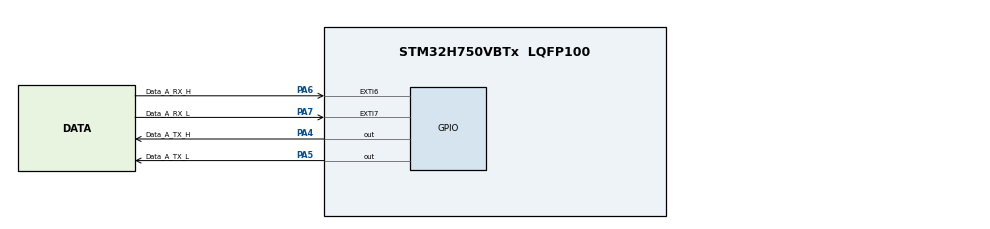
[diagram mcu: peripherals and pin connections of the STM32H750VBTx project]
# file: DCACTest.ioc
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CORTEX_M7.CPU_DCache=Enabled
CORTEX_M7.CPU_ICache=Enabled
FREERTOS.Tasks01=defaultTask,24,128,StartDefaultTask,Default,NULL,Dynamic,NULL,NULL
FREERTOS.configENABLE_FPU=0
Mcu.Family=STM32H7
Mcu.Name=STM32H750VBTx
Mcu.Package=LQFP100
NVIC.EXTI9_5_IRQn=true\:5\:0\:false\:false\:true\:true\:true\:true\:true
NVIC.PriorityGroup=NVIC_PRIORITYGROUP_4
NVIC.TIM5_IRQn=true\:15\:0\:false\:false\:true\:false\:false\:true\:true
NVIC.TimeBase=TIM5_IRQn
NVIC.TimeBaseIP=TIM5
PA13\ (JTMS/SWDIO).Mode=Serial_Wire
PA13\ (JTMS/SWDIO).Signal=DEBUG_JTMS-SWDIO
PA14\ (JTCK/SWCLK).Mode=Serial_Wire
PA14\ (JTCK/SWCLK).Signal=DEBUG_JTCK-SWCLK
PA4.GPIO_Label=Data_A_TX_H
PA4.GPIO_Speed=GPIO_SPEED_FREQ_VERY_HIGH
PA4.PinState=GPIO_PIN_SET
PA4.Signal=GPIO_Output
PA5.GPIO_Label=Data_A_TX_L
PA5.GPIO_Speed=GPIO_SPEED_FREQ_VERY_HIGH
PA5.PinState=GPIO_PIN_SET
PA5.Signal=GPIO_Output
PA6.GPIO_Label=Data_A_RX_H
PA6.GPIO_ModeDefaultEXTI=GPIO_MODE_IT_FALLING
PA6.GPIO_PuPd=GPIO_PULLUP
PA6.Signal=GPXTI6
PA7.GPIO_Label=Data_A_RX_L
PA7.GPIO_ModeDefaultEXTI=GPIO_MODE_IT_FALLING
PA7.GPIO_PuPd=GPIO_PULLUP
PA7.Signal=GPXTI7
PH0-OSC_IN\ (PH0).Mode=HSE-External-Oscillator
PH0-OSC_IN\ (PH0).Signal=RCC_OSC_IN
PH1-OSC_OUT\ (PH1).Mode=HSE-External-Oscillator
PH1-OSC_OUT\ (PH1).Signal=RCC_OSC_OUT
ProjectManager.HeapSize=0x200
ProjectManager.StackSize=0x400
ProjectManager.TargetToolchain=MDK-ARM V5.32
RCC.ADCFreq_Value=50390625
RCC.APB1Freq_Value=120000000
RCC.APB2Freq_Value=120000000
RCC.APB3Freq_Value=120000000
RCC.APB4Freq_Value=120000000
RCC.CortexFreq_Value=480000000
RCC.D1PPRE=RCC_APB3_DIV2
RCC.D2PPRE1=RCC_APB1_DIV2
RCC.D2PPRE2=RCC_APB2_DIV2
RCC.D3PPRE=RCC_APB4_DIV2
RCC.DIVM1=5
RCC.DIVN1=192
RCC.HCLKFreq_Value=240000000
RCC.HPRE=RCC_HCLK_DIV2
RCC.PLLSourceVirtual=RCC_PLLSOURCE_HSE
RCC.SYSCLKFreq_VALUE=480000000
RCC.SYSCLKSource=RCC_SYSCLKSOURCE_PLLCLK
RCC.USBFreq_Value=480000000
TIM6.Prescaler=240-1
VP_FREERTOS_VS_CMSIS_V2.Mode=CMSIS_V2
VP_SYS_VS_tim5.Mode=TIM5
VP_TIM6_VS_ClockSourceINT.Mode=Enable_Timer
board=custom

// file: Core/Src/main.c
/* USER CODE BEGIN Header */
/**
  ******************************************************************************
  * @file           : main.c
  * @brief          : Main program body
  ******************************************************************************
  * @attention
  *
  * Copyright (c) 2023 STMicroelectronics.
  * All rights reserved.
  *
  * This software is licensed under terms that can be found in the LICENSE file
  * in the root directory of this software component.
  * If no LICENSE file comes with this software, it is provided AS-IS.
  *
  ******************************************************************************
  */
/* USER CODE END Header */
#include "main.h"
#include "cmsis_os.h"
#include "tim.h"
#include "gpio.h"

/* USER CODE BEGIN Includes */
#include "usDelay.h"
/* USER CODE END Includes */

/* USER CODE BEGIN PTD */
uint32_t timer = 0;
/* USER CODE END PTD */

void SystemClock_Config(void);
void MX_FREERTOS_Init(void);

int main(void)
{

  /* Enable I-Cache---------------------------------------------------------*/
  SCB_EnableICache();

  /* Enable D-Cache---------------------------------------------------------*/
  SCB_EnableDCache();

  /* MCU Configuration--------------------------------------------------------*/

  /* Reset of all peripherals, Initializes the Flash interface and the Systick. */
  HAL_Init();

  /* Configure the system clock */
  SystemClock_Config();

  /* Initialize all configured peripherals */
  MX_GPIO_Init();
  MX_TIM6_Init();

  /* Init scheduler */
  osKernelInitialize();  /* Call init function for freertos objects (in freertos.c) */
  MX_FREERTOS_Init();

  /* Start scheduler */
  osKernelStart();

  /* We should never get here as control is now taken by the scheduler */
  /* Infinite loop */
  while (1)
  {

  }
}

void SystemClock_Config(void)
{
  RCC_OscInitTypeDef RCC_OscInitStruct = {0};
  RCC_ClkInitTypeDef RCC_ClkInitStruct = {0};

  /** Supply configuration update enable
  */
  HAL_PWREx_ConfigSupply(PWR_LDO_SUPPLY);

  /** Configure the main internal regulator output voltage
  */
  __HAL_PWR_VOLTAGESCALING_CONFIG(PWR_REGULATOR_VOLTAGE_SCALE1);

  while(!__HAL_PWR_GET_FLAG(PWR_FLAG_VOSRDY)) {}

  __HAL_RCC_SYSCFG_CLK_ENABLE();
  __HAL_PWR_VOLTAGESCALING_CONFIG(PWR_REGULATOR_VOLTAGE_SCALE0);

  while(!__HAL_PWR_GET_FLAG(PWR_FLAG_VOSRDY)) {}

  /** Initializes the RCC Oscillators according to the specified parameters
  * in the RCC_OscInitTypeDef structure.
  */
  RCC_OscInitStruct.OscillatorType = RCC_OSCILLATORTYPE_HSE;
  RCC_OscInitStruct.HSEState = RCC_HSE_ON;
  RCC_OscInitStruct.PLL.PLLState = RCC_PLL_ON;
  RCC_OscInitStruct.PLL.PLLSource = RCC_PLLSOURCE_HSE;
  RCC_OscInitStruct.PLL.PLLM = 5;
  RCC_OscInitStruct.PLL.PLLN = 192;
  RCC_OscInitStruct.PLL.PLLP = 2;
  RCC_OscInitStruct.PLL.PLLQ = 2;
  RCC_OscInitStruct.PLL.PLLR = 2;
  RCC_OscInitStruct.PLL.PLLRGE = RCC_PLL1VCIRANGE_2;
  RCC_OscInitStruct.PLL.PLLVCOSEL = RCC_PLL1VCOWIDE;
  RCC_OscInitStruct.PLL.PLLFRACN = 0;
  if (HAL_RCC_OscConfig(&RCC_OscInitStruct) != HAL_OK)
  {
    Error_Handler();
  }

  /** Initializes the CPU, AHB and APB buses clocks
  */
  RCC_ClkInitStruct.ClockType = RCC_CLOCKTYPE_HCLK|RCC_CLOCKTYPE_SYSCLK
                              |RCC_CLOCKTYPE_PCLK1|RCC_CLOCKTYPE_PCLK2
                              |RCC_CLOCKTYPE_D3PCLK1|RCC_CLOCKTYPE_D1PCLK1;
  RCC_ClkInitStruct.SYSCLKSource = RCC_SYSCLKSOURCE_PLLCLK;
  RCC_ClkInitStruct.SYSCLKDivider = RCC_SYSCLK_DIV1;
  RCC_ClkInitStruct.AHBCLKDivider = RCC_HCLK_DIV2;
  RCC_ClkInitStruct.APB3CLKDivider = RCC_APB3_DIV2;
  RCC_ClkInitStruct.APB1CLKDivider = RCC_APB1_DIV2;
  RCC_ClkInitStruct.APB2CLKDivider = RCC_APB2_DIV2;
  RCC_ClkInitStruct.APB4CLKDivider = RCC_APB4_DIV2;

  if (HAL_RCC_ClockConfig(&RCC_ClkInitStruct, FLASH_LATENCY_4) != HAL_OK)
  {
    Error_Handler();
  }
}

void HAL_TIM_PeriodElapsedCallback(TIM_HandleTypeDef *htim)
{
  if (htim->Instance == TIM5) {
    HAL_IncTick();
  }
}

void Error_Handler(void)
{
  __disable_irq();
  while (1)
  {
  }
}

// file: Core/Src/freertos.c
/* USER CODE BEGIN Header */
/**
  ******************************************************************************
  * File Name          : freertos.c
  * Description        : Code for freertos applications
  ******************************************************************************
  * @attention
  *
  * Copyright (c) 2023 STMicroelectronics.
  * All rights reserved.
  *
  * This software is licensed under terms that can be found in the LICENSE file
  * in the root directory of this software component.
  * If no LICENSE file comes with this software, it is provided AS-IS.
  *
  ******************************************************************************
  */
/* USER CODE END Header */

#include "FreeRTOS.h"
#include "task.h"
#include "main.h"
#include "cmsis_os.h"

/* USER CODE BEGIN Includes */
#include "Communication_IO.h"
/* USER CODE END Includes */

/* USER CODE BEGIN PD */
uint8_t String[10] = {0x34, 0x56, 0x03, 0x70, 0x66, 0x64, 0x56, 0x83, 0xAD, 0x04};
/* USER CODE END PD */

/* Definitions for defaultTask */
osThreadId_t defaultTaskHandle;
const osThreadAttr_t defaultTask_attributes = {
  .name = "defaultTask",
  .stack_size = 128 * 4,
  .priority = (osPriority_t) osPriorityNormal,
};

void StartDefaultTask(void *argument);

void MX_FREERTOS_Init(void); /* (MISRA C 2004 rule 8.1) */

void MX_FREERTOS_Init(void) {

  /* Create the thread(s) */
  /* creation of defaultTask */
  defaultTaskHandle = osThreadNew(StartDefaultTask, NULL, &defaultTask_attributes);

}

void StartDefaultTask(void *argument)
{
  /* USER CODE BEGIN StartDefaultTask */
  /* Infinite loop */
  for(;;)
  {
	  DCACNetSendString(String, 10);
    osDelay(10);
  }
  /* USER CODE END StartDefaultTask */
}
